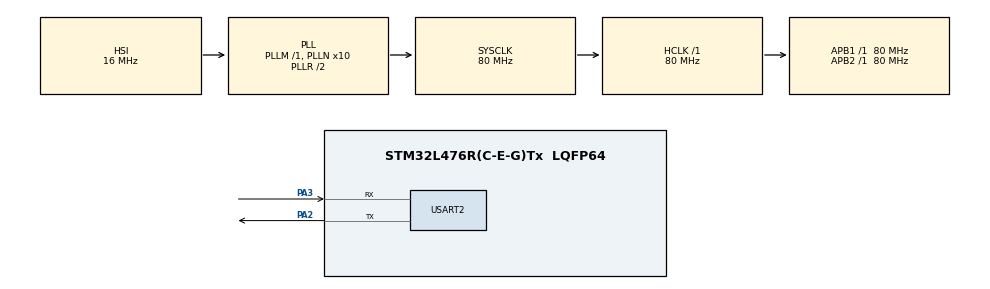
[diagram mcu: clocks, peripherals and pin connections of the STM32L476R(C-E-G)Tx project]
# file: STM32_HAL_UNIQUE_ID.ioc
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Mcu.Family=STM32L4
Mcu.Name=STM32L476R(C-E-G)Tx
Mcu.Package=LQFP64
NVIC.PriorityGroup=NVIC_PRIORITYGROUP_4
PA13\ (JTMS-SWDIO).Mode=Serial_Wire
PA13\ (JTMS-SWDIO).Signal=SYS_JTMS-SWDIO
PA14\ (JTCK-SWCLK).Mode=Serial_Wire
PA14\ (JTCK-SWCLK).Signal=SYS_JTCK-SWCLK
PA2.Mode=Asynchronous
PA2.Signal=USART2_TX
PA3.Mode=Asynchronous
PA3.Signal=USART2_RX
PH0-OSC_IN\ (PH0).Mode=HSE-External-Oscillator
PH0-OSC_IN\ (PH0).Signal=RCC_OSC_IN
PH1-OSC_OUT\ (PH1).Mode=HSE-External-Oscillator
PH1-OSC_OUT\ (PH1).Signal=RCC_OSC_OUT
ProjectManager.HeapSize=0x200
ProjectManager.StackSize=0x400
ProjectManager.TargetToolchain=STM32CubeIDE
RCC.ADCFreq_Value=64000000
RCC.AHBFreq_Value=80000000
RCC.APB1Freq_Value=80000000
RCC.APB1TimFreq_Value=80000000
RCC.APB2Freq_Value=80000000
RCC.APB2TimFreq_Value=80000000
RCC.CortexFreq_Value=80000000
RCC.HCLKFreq_Value=80000000
RCC.HSE_VALUE=8000000
RCC.HSI_VALUE=16000000
RCC.MSI_VALUE=4000000
RCC.PLLN=10
RCC.PLLSourceVirtual=RCC_PLLSOURCE_HSI
RCC.PREFETCH_ENABLE=1
RCC.SYSCLKFreq_VALUE=80000000
RCC.SYSCLKSource=RCC_SYSCLKSOURCE_PLLCLK
RCC.USBFreq_Value=64000000
RCC.VCOOutputFreq_Value=160000000
USART2.VirtualMode-Asynchronous=VM_ASYNC
board=NUCLEO-L476RG

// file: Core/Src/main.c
/* USER CODE BEGIN Header */
/**
  ******************************************************************************
  * @file           : main.c
  * @brief          : Main program body
  ******************************************************************************
  * @attention
  *
  * Copyright (c) 2022 STMicroelectronics.
  * All rights reserved.
  *
  * This software is licensed under terms that can be found in the LICENSE file
  * in the root directory of this software component.
  * If no LICENSE file comes with this software, it is provided AS-IS.
  *
  ******************************************************************************
  */
/* USER CODE END Header */
#include "main.h"
#include "usart.h"
#include "gpio.h"

/* USER CODE BEGIN Includes */
#include <stdio.h>
/* USER CODE END Includes */

void SystemClock_Config(void);

/* USER CODE BEGIN 0 */
int __io_putchar (int ch)
{
  HAL_UART_Transmit(&huart2, (uint8_t*)&ch, 1, HAL_MAX_DELAY);
  return ch;
}
/* USER CODE END 0 */

int main(void)
{

  /* MCU Configuration--------------------------------------------------------*/

  /* Reset of all peripherals, Initializes the Flash interface and the Systick. */
  HAL_Init();

  /* Configure the system clock */
  SystemClock_Config();

  /* Initialize all configured peripherals */
  MX_GPIO_Init();
  MX_USART2_UART_Init();
  /* USER CODE BEGIN 2 */

  //send UID information
  printf("%02X:%02X:%02X:%02X:%02X:%02X:%02X:%02X:%02X:%02X:%02X:%02X\r\n",
      *(uint8_t*)UID_BASE+0,
      *(uint8_t*)(UID_BASE+1),
      *(uint8_t*)(UID_BASE+2),
      *(uint8_t*)(UID_BASE+3),
      *(uint8_t*)(UID_BASE+4),
      *(uint8_t*)(UID_BASE+5),
      *(uint8_t*)(UID_BASE+6),
      *(uint8_t*)(UID_BASE+7),
      *(uint8_t*)(UID_BASE+8),
      *(uint8_t*)(UID_BASE+9),
      *(uint8_t*)(UID_BASE+10),
      *(uint8_t*)(UID_BASE+11)
  );

  /* USER CODE END 2 */

  /* Infinite loop */
  while (1)
  {

  }
}

void SystemClock_Config(void)
{
  RCC_OscInitTypeDef RCC_OscInitStruct = {0};
  RCC_ClkInitTypeDef RCC_ClkInitStruct = {0};

  /** Configure the main internal regulator output voltage
  */
  if (HAL_PWREx_ControlVoltageScaling(PWR_REGULATOR_VOLTAGE_SCALE1) != HAL_OK)
  {
    Error_Handler();
  }

  /** Initializes the RCC Oscillators according to the specified parameters
  * in the RCC_OscInitTypeDef structure.
  */
  RCC_OscInitStruct.OscillatorType = RCC_OSCILLATORTYPE_HSI;
  RCC_OscInitStruct.HSIState = RCC_HSI_ON;
  RCC_OscInitStruct.HSICalibrationValue = RCC_HSICALIBRATION_DEFAULT;
  RCC_OscInitStruct.PLL.PLLState = RCC_PLL_ON;
  RCC_OscInitStruct.PLL.PLLSource = RCC_PLLSOURCE_HSI;
  RCC_OscInitStruct.PLL.PLLM = 1;
  RCC_OscInitStruct.PLL.PLLN = 10;
  RCC_OscInitStruct.PLL.PLLP = RCC_PLLP_DIV7;
  RCC_OscInitStruct.PLL.PLLQ = RCC_PLLQ_DIV2;
  RCC_OscInitStruct.PLL.PLLR = RCC_PLLR_DIV2;
  if (HAL_RCC_OscConfig(&RCC_OscInitStruct) != HAL_OK)
  {
    Error_Handler();
  }

  /** Initializes the CPU, AHB and APB buses clocks
  */
  RCC_ClkInitStruct.ClockType = RCC_CLOCKTYPE_HCLK|RCC_CLOCKTYPE_SYSCLK
                              |RCC_CLOCKTYPE_PCLK1|RCC_CLOCKTYPE_PCLK2;
  RCC_ClkInitStruct.SYSCLKSource = RCC_SYSCLKSOURCE_PLLCLK;
  RCC_ClkInitStruct.AHBCLKDivider = RCC_SYSCLK_DIV1;
  RCC_ClkInitStruct.APB1CLKDivider = RCC_HCLK_DIV1;
  RCC_ClkInitStruct.APB2CLKDivider = RCC_HCLK_DIV1;

  if (HAL_RCC_ClockConfig(&RCC_ClkInitStruct, FLASH_LATENCY_4) != HAL_OK)
  {
    Error_Handler();
  }
}

void Error_Handler(void)
{
  __disable_irq();
  while (1)
  {
  }
}
